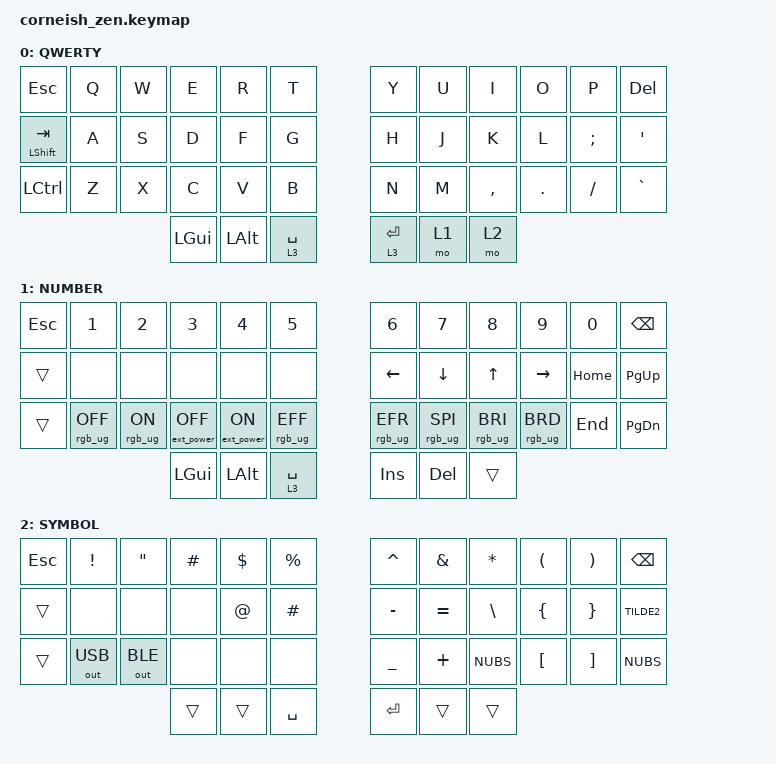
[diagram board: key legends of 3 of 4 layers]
/*
 * Copyright (c) 2020 The ZMK Contributors
 *
 * SPDX-License-Identifier: MIT
 */

#include <behaviors.dtsi>
#include <dt-bindings/zmk/bt.h>
#include <dt-bindings/zmk/ext_power.h>
#include <dt-bindings/zmk/keys.h>
#include <dt-bindings/zmk/outputs.h>
#include <dt-bindings/zmk/rgb.h>

/ {
    chosen {
        zmk,matrix_transform = &default_transform;

        // zmk,matrix_transform = &five_column_transform;
    };
};

/ {
    behaviors {
        td0: td0 {
            compatible = "zmk,behavior-tap-dance";
            label = "TD0";
            #binding-cells = <0>;
            bindings = <&kp LEFT_SHIFT>, <&kp CAPS>;
        };
    };

    keymap {
        compatible = "zmk,keymap";

        default_layer {
            display-name = "QWERTY";

            // --------------------------------------------------------------------------------------------------
            // | ESC  |  Q  |  W  |  E  |  R  |  T  |         |  Y  |  U   |  I  |  O  |  P  | DEL  |
            // | SHIFT|  A  |  S  |  D  |  F  |  G  |         |  H  |  J   |  K  |  L  |  ;  |  '   |
            // | CTRL |  Z  |  X  |  C  |  V  |  B  |         |  N  |  M   |  ,  |  .  |  /  |  `   |

            bindings = <
&kp ESC         &kp Q    &kp W    &kp E    &kp R    &kp T          &kp Y    &kp U    &kp I     &kp O    &kp P    &kp DEL
&mt LSHIFT TAB  &kp A    &kp S    &kp D    &kp F    &kp G          &kp H    &kp J    &kp K     &kp L    &kp SEMI &kp SQT
&kp LCTRL       &kp Z    &kp X    &kp C    &kp V    &kp B          &kp N    &kp M    &kp COMMA &kp DOT  &kp FSLH &kp GRAVE
                         &kp LGUI  &kp LALT &lt 3 SPACE        &lt 3 ENTER  &mo 1 &mo 2
            >;
        };


        lower_layer {
            display-name = "NUMBER";

            // ---------------------------------------------------------------------------------------------------------
            // | ESC  |  1  |  2  |  3  |  4  |  5  |                         |  6  |  7  |  8  |  9  |  10 | BKSP |
            // | BTCLR| BT1 | BT2 | BT3 | BT4 | BT5 |                         | LFT | DWN |  UP | RGT | HOME| PGUP |
            // | CTRL |     |     |     |     |     |                         |     |     |     |     | END | PGDN |
            //                    | GUI | ALT | SPC |                         | ENT | ALT |     |

            bindings = <
&kp ESC &kp N1           &kp N2          &kp N3             &kp N4            &kp N5                 &kp N6           &kp N7           &kp N8           &kp N9           &kp N0    &kp BKSP
&trans  &none            &none           &none              &none             &none                  &kp LEFT         &kp DOWN         &kp UP           &kp RIGHT        &kp HOME  &kp PG_UP
&trans  &rgb_ug RGB_OFF  &rgb_ug RGB_ON  &ext_power EP_OFF  &ext_power EP_ON  &rgb_ug RGB_EFF        &rgb_ug RGB_EFR  &rgb_ug RGB_SPI  &rgb_ug RGB_BRI  &rgb_ug RGB_BRD  &kp END   &kp PG_DN
                                         &kp LGUI           &kp LALT          &lt 3 SPACE            &kp INS          &kp DEL          &trans
            >;
        };


        raise_layer {
            display-name = "SYMBOL";

            // ---------------------------------------------------------------------------------------------------------
            // | ESC  |  !  |  "  |  #  |  $  |  %  |                       |  ^  |  &  |  *  |  (  |  )  | BKSP |
            // | SHFT |     |     |     |  @  |  #  |                       |  -  |  =  |  #  |  {  |  }  |  ~   |
            // | CTRL |     |     |     |     |     |                       |  _  |  +  | "|" |  [  |  ]  | "|"  |
            //                    | GUI | ALT | SPC |                       | ENT |     |     |

            bindings = <
&kp ESC &kp EXCL      &kp DQT       &kp HASH  &kp DLLR  &kp PRCNT            &kp CARET  &kp AMPS   &kp ASTRK &kp LPAR  &kp RPAR  &kp BKSP
&trans  &none         &none         &none     &kp AT    &kp HASH             &kp MINUS  &kp EQUAL  &kp BSLH  &kp LBRC  &kp RBRC  &kp TILDE2
&trans  &out OUT_USB  &out OUT_BLE  &none     &none     &none                &kp UNDER  &kp PLUS   &kp NUBS  &kp LBKT  &kp RBKT  &kp NUBS
                                    &trans    &trans    &kp SPACE            &kp RET    &trans     &trans
            >;
        };


        fn_layer {
            display-name = "Fn";

            // -----------------------------------------------------------------------------------------------------------
            // | ESC  |  F1  |  F2  |  F3  |  F4  |  F5                 |  F6 |  F7  |  F8  |  F9  |  F10  |  F11  |
            // | CTRL |      |      |      | sysr |                     |     |  -   |  =   |      |  prts |  F12  |
            // | SHFT | btc  | bt0  |  bt1 | bt2  |  bt3                | mut | vdn  | vup  |      |  sclk |  brk  |
            //                    | GUI    | ALT  | SPC                 |     | ENT |  LWR  | RSE  |

            bindings = <
&kp ESC  &kp F1         &kp F2       &kp F3       &kp F4         &kp F5               &kp F6       &kp F7  &kp F8  &kp F9  &kp F10          &kp F11
&trans  &trans          &trans       &trans       &sys_reset     &trans               &trans       &trans  &trans  &kp PRINTSCREEN  &kp F12
&trans  &bt BT_CLR_ALL  &bt BT_SEL 0 &bt BT_SEL 1 &bt BT_SEL 2   &bt BT_SEL 3         &kp C_MUTE   &kp C_VOL_DN &kp C_VOL_UP &trans  &kp SCROLLLOCK   &kp PAUSE_BREAK
                                     &trans       &trans       &trans                 &trans       &trans  &trans
            >;
        };
    };
};
